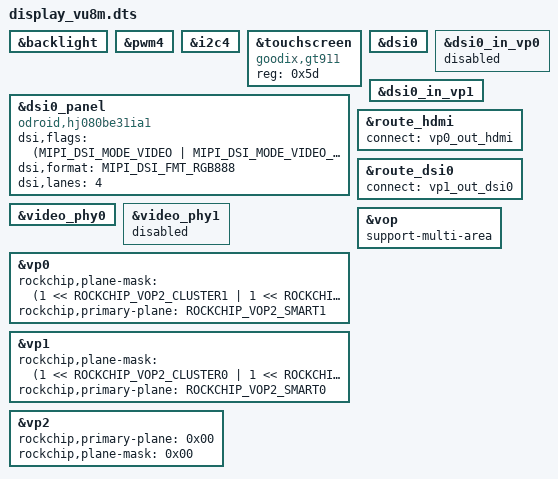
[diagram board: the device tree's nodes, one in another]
/dts-v1/;
/plugin/;

#include <dt-bindings/gpio/gpio.h>
#include <dt-bindings/pinctrl/rockchip.h>
#include <dt-bindings/display/drm_mipi_dsi.h>
#include <dt-bindings/display/rockchip_vop.h>
#include <dt-bindings/interrupt-controller/irq.h>
#include <dt-bindings/interrupt-controller/arm-gic.h>

/{
	fragment@0 {
		target = <&backlight>;

		__overlay__ {
			status = "okay";
		};
	};

	fragment@1 {
		target = <&pwm4>;

		__overlay__ {
			status = "okay";
		};
	};

	fragment@2 {
		target = <&i2c4>;

		__overlay__ {
			status = "okay";
		};
	};

	fragment@3 {
		target = <&touchscreen>;

		#address-cells = <1>;
		#size-cells = <0>;

		__overlay__ {
			status = "okay";

			compatible = "goodix,gt911";
			reg = <0x5d>;
		};
	};

	fragment@4 {
		target = <&dsi0>;

		__overlay__ {
			status = "okay";
		};
	};

	fragment@5 {
		target = <&dsi0_panel>;

		__overlay__ {
			status = "okay";
			compatible = "odroid,hj080be31ia1";

			dsi,flags = <(MIPI_DSI_MODE_VIDEO | MIPI_DSI_MODE_VIDEO_BURST |
					MIPI_DSI_MODE_EOT_PACKET)>;
			dsi,format = <MIPI_DSI_FMT_RGB888>;
			dsi,lanes = <4>;
		};
	};

	fragment@6 {
		target = <&dsi0_in_vp0>;

		__overlay__ {
			status = "disabled";
		};
	};

	fragment@7 {
		target = <&dsi0_in_vp1>;

		__overlay__ {
			status = "okay";
		};
	};

	fragment@8 {
		target = <&route_hdmi>;

		__overlay__ {
			status = "okay";
			connect = <&vp0_out_hdmi>;
		};
	};

	fragment@9 {
		target = <&route_dsi0>;

		__overlay__ {
			status = "okay";
			connect = <&vp1_out_dsi0>;
		};
	};

	fragment@10 {
		target = <&video_phy0>;

		__overlay__ {
			status = "okay";
		};
	};

	fragment@11 {
		target = <&video_phy1>;

		__overlay__ {
			status = "disabled";
		};
	};

	fragment@12 {
		target = <&vp0>;

		__overlay__ {
			rockchip,plane-mask = <(1 << ROCKCHIP_VOP2_CLUSTER1
					| 1 << ROCKCHIP_VOP2_ESMART1
					| 1 << ROCKCHIP_VOP2_SMART1)>;
			rockchip,primary-plane = <ROCKCHIP_VOP2_SMART1>;
		};
	};

	fragment@13 {
		target = <&vp1>;

		__overlay__ {
			rockchip,plane-mask = <(1 << ROCKCHIP_VOP2_CLUSTER0
					| 1 << ROCKCHIP_VOP2_ESMART0
					| 1 << ROCKCHIP_VOP2_SMART0)>;
			rockchip,primary-plane = <ROCKCHIP_VOP2_SMART0>;
		};
	};

	fragment@14 {
		target = <&vp2>;

		__overlay__ {
			rockchip,primary-plane = <0x00>;
			rockchip,plane-mask = <0x00>;
		};
	};

	fragment@15 {
		target = <&vop>;

		__overlay__ {
			support-multi-area;
		};
	};
};
